# iostm32f205zx register map
Registers are 32-bit, access not given, no defined reset value unless marked. A register's access mark holds for its fields unless they carry their own. Addresses are absolute; registers are grouped by the start of their names; [hi:lo] are bit positions; {n}, {i} and the like mark numbered series.

## SPI3
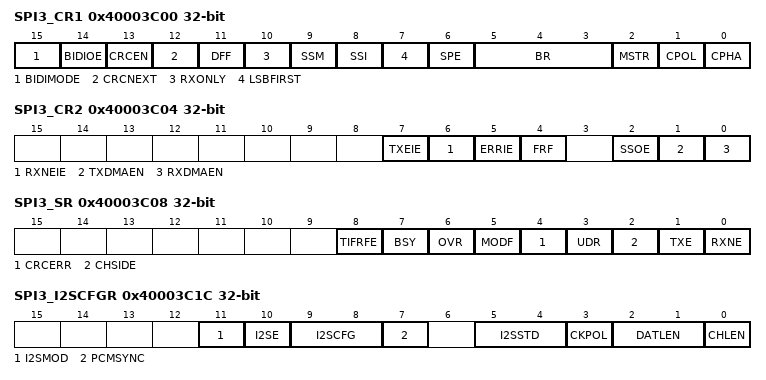
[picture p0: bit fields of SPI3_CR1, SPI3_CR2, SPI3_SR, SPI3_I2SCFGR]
0x40003C00 SPI3_CR1
  [15] BIDIMODE, [14] BIDIOE, [13] CRCEN, [12] CRCNEXT, [11] DFF, [10] RXONLY, [9] SSM, [8] SSI, [7] LSBFIRST, [6] SPE, [5:3] BR, [2] MSTR, [1] CPOL, [0] CPHA
0x40003C04 SPI3_CR2
  [7] TXEIE, [6] RXNEIE, [5] ERRIE, [4] FRF, [2] SSOE, [1] TXDMAEN, [0] RXDMAEN
0x40003C08 SPI3_SR
  [8] TIFRFE, [7] BSY, [6] OVR, [5] MODF, [4] CRCERR, [3] UDR, [2] CHSIDE, [1] TXE, [0] RXNE
0x40003C0C SPI3_DR
  [15:0] DR
0x40003C10 SPI3_CRCPR
  [15:0] CRCPOLY
0x40003C14 SPI3_RXCRCR
  [15:0] RxCRC
0x40003C18 SPI3_TXCRCR
  [15:0] TxCRC
0x40003C1C SPI3_I2SCFGR
  [11] I2SMOD, [10] I2SE, [9:8] I2SCFG, [7] PCMSYNC, [5:4] I2SSTD, [3] CKPOL, [2:1] DATLEN, [0] CHLEN
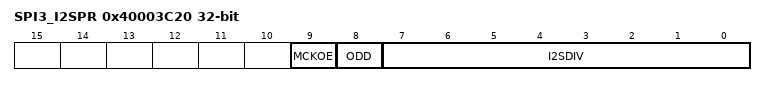
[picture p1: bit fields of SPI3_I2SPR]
0x40003C20 SPI3_I2SPR
  [9] MCKOE, [8] ODD, [7:0] I2SDIV

## SDIO
0x40012C00 SDIO_POWER
  [1:0] PWRCTRL
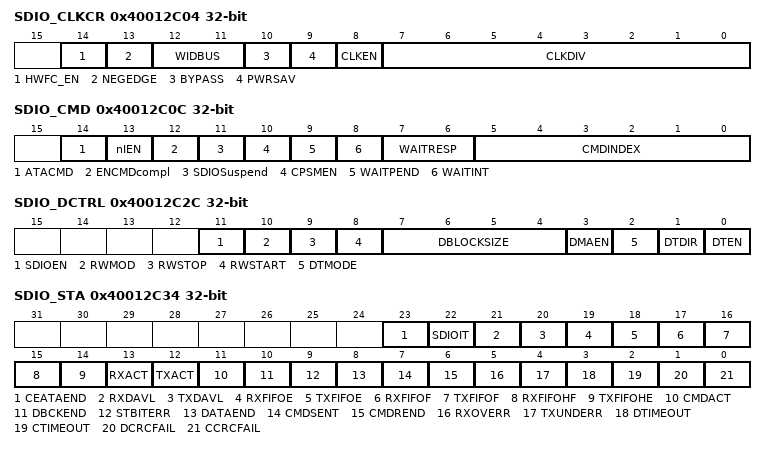
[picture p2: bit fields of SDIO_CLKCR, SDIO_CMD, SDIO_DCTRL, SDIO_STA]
0x40012C04 SDIO_CLKCR
  [14] HWFC_EN, [13] NEGEDGE, [12:11] WIDBUS, [10] BYPASS, [9] PWRSAV, [8] CLKEN, [7:0] CLKDIV
0x40012C08 SDIO_ARG
0x40012C0C SDIO_CMD
  [14] ATACMD, [13] nIEN, [12] ENCMDcompl, [11] SDIOSuspend, [10] CPSMEN, [9] WAITPEND, [8] WAITINT, [7:6] WAITRESP, [5:0] CMDINDEX
0x40012C10 SDIO_RESPCMD
  [5:0] RESPCMD
{0x40012C10+4i} SDIO_RESP{i} (i=1..4)
0x40012C24 SDIO_DTIMER
0x40012C28 SDIO_DLEN
  [24:0] DATALENGTH
0x40012C2C SDIO_DCTRL
  [11] SDIOEN, [10] RWMOD, [9] RWSTOP, [8] RWSTART, [7:4] DBLOCKSIZE, [3] DMAEN, [2] DTMODE, [1] DTDIR, [0] DTEN
0x40012C30 SDIO_DCOUNT
  [24:0] DATACOUNT
0x40012C34 SDIO_STA
  [23] CEATAEND, [22] SDIOIT, [21] RXDAVL, [20] TXDAVL, [19] RXFIFOE, [18] TXFIFOE, [17] RXFIFOF, [16] TXFIFOF, [15] RXFIFOHF, [14] TXFIFOHE, [13] RXACT, [12] TXACT, [11] CMDACT, [10] DBCKEND, [9] STBITERR, [8] DATAEND, [7] CMDSENT, [6] CMDREND, [5] RXOVERR, [4] TXUNDERR, [3] DTIMEOUT, [2] CTIMEOUT, [1] DCRCFAIL, [0] CCRCFAIL
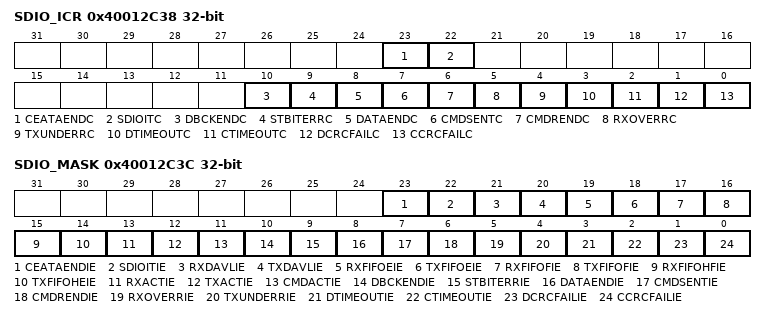
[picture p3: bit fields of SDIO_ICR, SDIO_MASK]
0x40012C38 SDIO_ICR
  [23] CEATAENDC, [22] SDIOITC, [10] DBCKENDC, [9] STBITERRC, [8] DATAENDC, [7] CMDSENTC, [6] CMDRENDC, [5] RXOVERRC, [4] TXUNDERRC, [3] DTIMEOUTC, [2] CTIMEOUTC, [1] DCRCFAILC, [0] CCRCFAILC
0x40012C3C SDIO_MASK
  [23] CEATAENDIE, [22] SDIOITIE, [21] RXDAVLIE, [20] TXDAVLIE, [19] RXFIFOEIE, [18] TXFIFOEIE, [17] RXFIFOFIE, [16] TXFIFOFIE, [15] RXFIFOHFIE, [14] TXFIFOHEIE, [13] RXACTIE, [12] TXACTIE, [11] CMDACTIE, [10] DBCKENDIE, [9] STBITERRIE, [8] DATAENDIE, [7] CMDSENTIE, [6] CMDRENDIE, [5] RXOVERRIE, [4] TXUNDERRIE, [3] DTIMEOUTIE, [2] CTIMEOUTIE, [1] DCRCFAILIE, [0] CCRCFAILIE
0x40012C48 SDIO_FIFOCNT
  [23:0] FIFOCOUNT
0x40012C80 SDIO_FIFO

## USART1
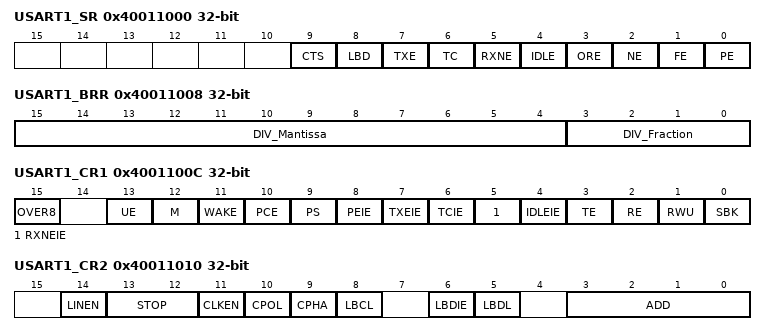
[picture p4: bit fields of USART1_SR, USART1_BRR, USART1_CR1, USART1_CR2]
0x40011000 USART1_SR
  [9] CTS, [8] LBD, [7] TXE, [6] TC, [5] RXNE, [4] IDLE, [3] ORE, [2] NE, [1] FE, [0] PE
0x40011004 USART1_DR
  [8:0] DR
0x40011008 USART1_BRR
  [15:4] DIV_Mantissa, [3:0] DIV_Fraction
0x4001100C USART1_CR1
  [15] OVER8, [13] UE, [12] M, [11] WAKE, [10] PCE, [9] PS, [8] PEIE, [7] TXEIE, [6] TCIE, [5] RXNEIE, [4] IDLEIE, [3] TE, [2] RE, [1] RWU, [0] SBK
0x40011010 USART1_CR2
  [14] LINEN, [13:12] STOP, [11] CLKEN, [10] CPOL, [9] CPHA, [8] LBCL, [6] LBDIE, [5] LBDL, [3:0] ADD
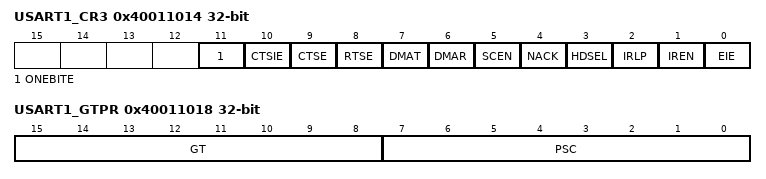
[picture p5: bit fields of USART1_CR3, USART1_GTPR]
0x40011014 USART1_CR3
  [11] ONEBITE, [10] CTSIE, [9] CTSE, [8] RTSE, [7] DMAT, [6] DMAR, [5] SCEN, [4] NACK, [3] HDSEL, [2] IRLP, [1] IREN, [0] EIE
0x40011018 USART1_GTPR
  [15:8] GT, [7:0] PSC

## USART2
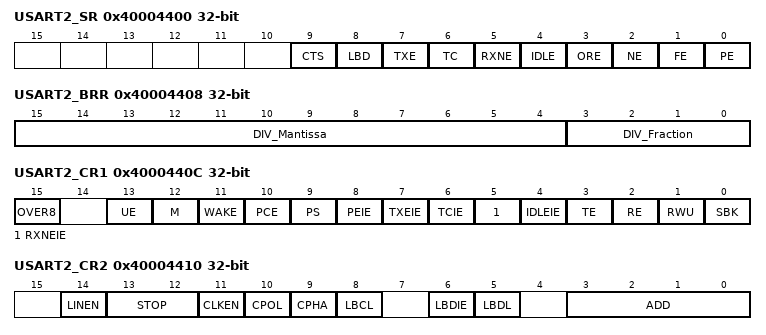
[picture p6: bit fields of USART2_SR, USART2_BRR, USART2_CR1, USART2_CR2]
0x40004400 USART2_SR
  [9] CTS, [8] LBD, [7] TXE, [6] TC, [5] RXNE, [4] IDLE, [3] ORE, [2] NE, [1] FE, [0] PE
0x40004404 USART2_DR
  [8:0] DR
0x40004408 USART2_BRR
  [15:4] DIV_Mantissa, [3:0] DIV_Fraction
0x4000440C USART2_CR1
  [15] OVER8, [13] UE, [12] M, [11] WAKE, [10] PCE, [9] PS, [8] PEIE, [7] TXEIE, [6] TCIE, [5] RXNEIE, [4] IDLEIE, [3] TE, [2] RE, [1] RWU, [0] SBK
0x40004410 USART2_CR2
  [14] LINEN, [13:12] STOP, [11] CLKEN, [10] CPOL, [9] CPHA, [8] LBCL, [6] LBDIE, [5] LBDL, [3:0] ADD
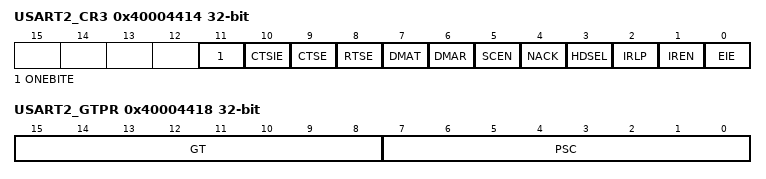
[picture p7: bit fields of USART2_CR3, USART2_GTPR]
0x40004414 USART2_CR3
  [11] ONEBITE, [10] CTSIE, [9] CTSE, [8] RTSE, [7] DMAT, [6] DMAR, [5] SCEN, [4] NACK, [3] HDSEL, [2] IRLP, [1] IREN, [0] EIE
0x40004418 USART2_GTPR
  [15:8] GT, [7:0] PSC
